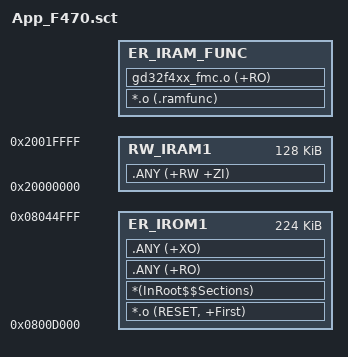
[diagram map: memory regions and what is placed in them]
; App scatter file for GD32F470VET6 (APP1 region)
; APP1 : 0x0800D000 - 0x08044FFF (224KB)

LR_IROM1 0x0800D000 0x00038000  {
  ER_IROM1 0x0800D000 0x00038000  {
   *.o (RESET, +First)
   *(InRoot$$Sections)
   .ANY (+RO)
   .ANY (+XO)
  }
  RW_IRAM1 0x20000000 0x00020000  {
   .ANY (+RW +ZI)
  }
  ER_IRAM_FUNC +0  {
   *.o (.ramfunc)
   gd32f4xx_fmc.o (+RO)
  }
}
